# MU3E_RING_BUFFER_CAM register map
Vendor: Mu3e; Series: MU3E_FPGA_IP; File version: 26.1.4.0402
CMSIS-SVD description of the ring_buffer_cam CSR window.
Registers are 32-bit, read-only, reset 0x0 unless marked. A register's access mark holds for its fields unless they carry their own. Offsets are from the block's base; lines under a group give offsets from that group; [hi:lo] are bit positions; {n}, {i} and the like mark numbered series; 'fields as' and 'values as' point back to an identical list; <NAME> marks a mode.

## Memory map
0x00000000 RING_BUFFER_CAM_CSR size 0x80 — Relative CSR aperture for the ring-buffer CAM.

## RING_BUFFER_CAM_CSR — Relative CSR aperture for the ring-buffer CAM.
Base 0x00000000
0x00 UID reset 0x5242434D — Software-visible IP identifier. Default ASCII "RBCM".
  [31:0] value — Compile-time or integration-time UID word. Default ASCII "RBCM".
0x04 META rw — Read-multiplexed metadata word. Write 0=VERSION, 1=DATE, 2=GIT, 3=INSTANCE_ID and read back the selected page.
  [1:0] page_sel — Selects the metadata page.
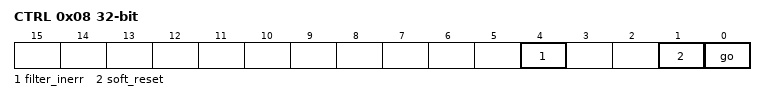
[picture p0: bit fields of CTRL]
0x08 CTRL rw — Go, soft-reset, and filter control word.
  [4] filter_inerr — Filters ingress hits that carry timestamp error.
  [1] soft_reset write-1-sets — Requests a local soft reset pulse.
  [0] go — Enable timestamp ordering and pop logic.
0x0C EXPECTED_LATENCY rw — Read-pointer delay target in cycles.
  [31:0] value — Expected latency target.
0x10 FILL_LEVEL — Live fill-level estimate derived from push, pop, and overwrite counters.
  [31:0] value — Ring-buffer fill-level estimate.
0x14 INERR_COUNT — Count of filtered ingress timestamp-error hits.
  [31:0] value — Filtered ingress-error hit count.
0x18 PUSH_COUNT — Total accepted push operations.
  [31:0] value — Accepted push count.
0x1C POP_COUNT — Total drained hits.
  [31:0] value — Drained hit count.
0x20 OVERWRITE_COUNT — Total overwrite events.
  [31:0] value — Overwrite-event count.
0x24 CACHE_MISS_COUNT — Total cache-miss or empty-search events.
  [31:0] value — Cache-miss or empty-search count.
